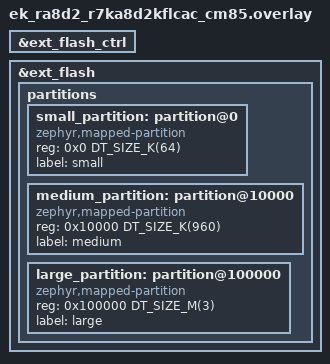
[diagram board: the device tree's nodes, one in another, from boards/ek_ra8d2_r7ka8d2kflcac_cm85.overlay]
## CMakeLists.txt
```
# SPDX-License-Identifier: Apache-2.0

cmake_minimum_required(VERSION 3.28.0)
find_package(Zephyr REQUIRED HINTS $ENV{ZEPHYR_BASE})
project(littlefs)

FILE(GLOB app_sources src/*.c)
# LittleFS opens files for RW by default if no flags given and crashes,
# instead of returning error when attempting to perform operation that
# a file has not been opened for.
target_compile_definitions(app PRIVATE
  BYPASS_FS_OPEN_FLAGS_LFS_ASSERT_CRASH
  BYPASS_FS_OPEN_FLAGS_LFS_RW_IS_DEFAULT
)
target_sources(app PRIVATE
  ${app_sources}
  ../common/test_fs_util.c
  ../common/test_fs_open_flags.c
  ../common/test_fs_dirops.c
  ../common/test_fs_basic.c
  ../common/test_fs_mount_flags.c
  ../common/test_fs_mkfs.c
  ../common/test_fs_gc.c
)
```

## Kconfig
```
# SPDX-License-Identifier: Apache-2.0
# Copyright (c) 2020 Nordic Semiconductor ASA

mainmenu "littlefs core functionality test"

source "Kconfig.zephyr"

config APP_TEST_CUSTOM
	bool "Select to test additional custom filesystem configurations"
```

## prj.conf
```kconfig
CONFIG_FILE_SYSTEM=y
CONFIG_FILE_SYSTEM_MKFS=y
CONFIG_FILE_SYSTEM_GC=y
CONFIG_FILE_SYSTEM_LITTLEFS=y
CONFIG_MAIN_STACK_SIZE=4096

# Performance tests need custom buffer allocation
CONFIG_COMMON_LIBC_MALLOC_ARENA_SIZE=8192

# FS abstraction layer is noisy so it's off.  Turn it on to see the
# littlefs configuration parameters.
#CONFIG_LOG=y
#CONFIG_FS_LOG_LEVEL_DBG=y

CONFIG_FLASH=y
CONFIG_FLASH_MAP=y

CONFIG_ZTEST=y
CONFIG_ZTEST_STACK_SIZE=4096
```

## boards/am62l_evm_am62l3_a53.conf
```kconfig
#
# SPDX-FileCopyrightText: 2026 Texas Instruments Incorporated
#
# SPDX-License-Identifier: Apache-2.0
#

CONFIG_FS_LITTLEFS_PROG_SIZE=256
CONFIG_FS_LITTLEFS_CACHE_SIZE=256
```

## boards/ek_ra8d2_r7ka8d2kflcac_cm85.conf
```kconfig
# Copyright (c) 2026 Renesas Electronics Corporation
# SPDX-License-Identifier: Apache-2.0

CONFIG_FS_LITTLEFS_PROG_SIZE=128
CONFIG_FS_LITTLEFS_CACHE_SIZE=128
CONFIG_HEAP_MEM_POOL_SIZE=2048
```

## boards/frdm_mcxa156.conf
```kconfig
# Copyright 2025 NXP
# SPDX-License-Identifier: Apache-2.0

CONFIG_FS_LITTLEFS_PROG_SIZE=128
CONFIG_FS_LITTLEFS_CACHE_SIZE=256
```

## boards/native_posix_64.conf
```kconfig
CONFIG_FLASH_NATIVE_POSIX_SECTOR_SIZE=4
```

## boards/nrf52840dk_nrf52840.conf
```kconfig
#
# Copyright (c) 2019 Peter Bigot Consulting, LLC
# Copyright (c) 2019 Nordic Semiconductor ASA
#
# SPDX-License-Identifier: Apache-2.0
#

CONFIG_NORDIC_QSPI_NOR_FLASH_LAYOUT_PAGE_SIZE=4096
```

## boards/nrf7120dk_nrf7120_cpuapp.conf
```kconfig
#
# Copyright (c) 2026 Nordic Semiconductor ASA
#
# SPDX-License-Identifier: Apache-2.0
#

CONFIG_FLASH_MSPI_NOR_LAYOUT_PAGE_SIZE=4096
```

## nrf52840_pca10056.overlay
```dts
/*
 * Copyright (c) 2019 Peter Bigot Consulting, LLC
 *
 * SPDX-License-Identifier: Apache-2.0
 */

&mx25r64 {
	partitions {
		compatible = "fixed-partitions";
		#address-cells = <1>;
		#size-cells = <1>;

 		partition@0 {
			label = "small";
			reg = <0x00000000 0x00010000>;
		};
		partition@200000 {
			label = "medium";
			reg = <0x00010000 0x000F0000>;
		};
		partition@220000 {
			label = "large";
			reg = <0x00100000 0x00300000>;
		};
	};
};
```

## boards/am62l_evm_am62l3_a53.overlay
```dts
/*
 * SPDX-FileCopyrightText: 2026 Texas Instruments Incorporated
 *
 * SPDX-License-Identifier: Apache-2.0
 */

&flash0_memory {
	partitions {
		compatible = "fixed-partitions";
		#address-cells = <1>;
		#size-cells = <1>;

		small_partition: partition@0 {
			label = "small";
			reg = <0x00000000 DT_SIZE_M(4)>;
		};

		medium_partition: partition@400000 {
			label = "medium";
			reg = <0x00400000 DT_SIZE_M(6)>;
		};

		large_partition: partition@800000 {
			label = "large";
			reg = <0x00800000 DT_SIZE_M(8)>;
		};
	};
};
```

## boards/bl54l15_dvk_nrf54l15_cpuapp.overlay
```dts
/*
 * Copyright (c) 2024 Nordic Semiconductor ASA
 * Copyright (c) 2025 Ezurio LLC
 *
 * SPDX-License-Identifier: Apache-2.0
 */

/delete-node/ &slot0_ns_partition;
/delete-node/ &slot1_partition;
/delete-node/ &slot1_ns_partition;

&cpuapp_rram {
	partitions {
		compatible = "fixed-partitions";
		#address-cells = <1>;
		#size-cells = <1>;

		small_partition: partition@67000 {
			label = "small";
			reg = <0x00067000 0x00010000>;
		};
	};
};
```

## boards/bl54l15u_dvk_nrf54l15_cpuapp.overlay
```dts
/*
 * Copyright (c) 2024 Nordic Semiconductor ASA
 * Copyright (c) 2025 Ezurio LLC
 *
 * SPDX-License-Identifier: Apache-2.0
 */

/delete-node/ &slot1_partition;

&cpuapp_rram {
	partitions {
		compatible = "fixed-partitions";
		#address-cells = <1>;
		#size-cells = <1>;

		small_partition: partition@b6000 {
			reg = <0x000b6000 0x00010000>;
			label = "small";
		};
	};
};
```

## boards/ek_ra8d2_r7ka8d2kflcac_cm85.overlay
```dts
/*
 * Copyright (c) 2026 Renesas Electronics Corporation
 * SPDX-License-Identifier: Apache-2.0
 */

/delete-node/ &storage_partition;

&ext_flash_ctrl {
	status = "okay";
};

&ext_flash {
	status = "okay";

	partitions {
		ranges;
		#address-cells = <1>;
		#size-cells = <1>;

		small_partition: partition@0 {
			compatible = "zephyr,mapped-partition";
			reg = <0x0 DT_SIZE_K(64)>;
			label = "small";
		};

		medium_partition: partition@10000 {
			compatible = "zephyr,mapped-partition";
			reg = <0x10000 DT_SIZE_K(960)>;
			label = "medium";
		};

		large_partition: partition@100000 {
			compatible = "zephyr,mapped-partition";
			reg = <0x100000 DT_SIZE_M(3)>;
			label = "large";
		};
	};
};
```

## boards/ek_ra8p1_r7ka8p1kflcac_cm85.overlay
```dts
/*
 * Copyright (c) 2026 Renesas Electronics Corporation
 * SPDX-License-Identifier: Apache-2.0
 */

/delete-node/ &storage_partition;

&ext_flash_ctrl {
	status = "okay";
};

&ext_flash {
	status = "okay";

	partitions {
		#address-cells = <1>;
		#size-cells = <1>;
		ranges;

		small_partition: partition@0 {
			compatible = "zephyr,mapped-partition";
			label = "small";
			reg = <0x0 DT_SIZE_K(64)>;
		};

		medium_partition: partition@10000 {
			compatible = "zephyr,mapped-partition";
			label = "medium";
			reg = <0x10000 DT_SIZE_K(960)>;
		};

		large_partition: partition@100000 {
			compatible = "zephyr,mapped-partition";
			label = "large";
			reg = <0x100000 DT_SIZE_M(3)>;
		};
	};
};
```

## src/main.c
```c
/*
 * Copyright (c) 2019 Peter Bigot Consulting, LLC
 *
 * SPDX-License-Identifier: Apache-2.0
 */

#include <string.h>
#include <zephyr/ztest.h>
#include "testfs_tests.h"
#include "testfs_lfs.h"

ZTEST_SUITE(littlefs, NULL, NULL, NULL, NULL, NULL);
```

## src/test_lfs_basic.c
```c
/*
 * Copyright (c) 2019 Peter Bigot Consulting, LLC
 *
 * SPDX-License-Identifier: Apache-2.0
 */

/* Basic littlefs operations:
 * * create
 * * write
 * * stat
 * * read
 * * seek
 * * tell
 * * truncate
 * * unlink
 * * sync
 */

#include <string.h>
#include <zephyr/ztest.h>
#include "testfs_tests.h"
#include "testfs_lfs.h"
#include <lfs.h>

#include <zephyr/fs/littlefs.h>

static int mount(struct fs_mount_t *mp)
{
	TC_PRINT("mounting %s\n", mp->mnt_point);

	zassert_equal(fs_mount(mp), 0,
		      "mount failed");

	return TC_PASS;
}

static int clear_partition(struct fs_mount_t *mp)
{
	TC_PRINT("clearing partition %s\n", mp->mnt_point);

	zassert_equal(testfs_lfs_wipe_partition(mp),
		      TC_PASS,
		      "failed to wipe partition");

	return TC_PASS;
}

static int clean_statvfs(const struct fs_mount_t *mp)
{
	struct fs_statvfs stat;

	TC_PRINT("checking clean statvfs of %s\n", mp->mnt_point);

	zassert_equal(fs_statvfs(mp->mnt_point, &stat), 0,
		      "statvfs failed");

	TC_PRINT("%s: bsize %lu ; frsize %lu ; blocks %lu ; bfree %lu\n",
		 mp->mnt_point,
		 stat.f_bsize, stat.f_frsize, stat.f_blocks, stat.f_bfree);
	zassert_equal(stat.f_bsize, CONFIG_FS_LITTLEFS_PROG_SIZE,
		      "bsize fail");
	zassert_equal(stat.f_bfree, stat.f_blocks - 2U,
		      "bfree fail");

	return TC_PASS;
}

static int check_medium(void)
{
	struct fs_mount_t *mp = &testfs_medium_mnt;
	struct fs_statvfs stat;

	zassert_equal(clear_partition(mp), TC_PASS,
		      "clear partition failed");

	zassert_equal(fs_mount(mp), 0,
		      "medium mount failed");

	zassert_equal(fs_statvfs(mp->mnt_point, &stat), 0,
		      "statvfs failed");

	TC_PRINT("%s: bsize %lu ; frsize %lu ; blocks %lu ; bfree %lu\n",
		 mp->mnt_point,
		 stat.f_bsize, stat.f_frsize, stat.f_blocks, stat.f_bfree);
	zassert_equal(stat.f_bsize, MEDIUM_IO_SIZE,
		      "bsize fail");
	zassert_equal(stat.f_bfree, stat.f_blocks - 2U,
		      "bfree fail");

	zassert_equal(fs_unmount(mp), 0,
		      "medium unmount failed");

	return TC_PASS;
}

static int check_large(void)
{
	struct fs_mount_t *mp = &testfs_large_mnt;
	struct fs_statvfs stat;

	zassert_equal(clear_partition(mp), TC_PASS,
		      "clear partition failed");

	zassert_equal(fs_mount(mp), 0,
		      "large mount failed");

	zassert_equal(fs_statvfs(mp->mnt_point, &stat), 0,
		      "statvfs failed");

	TC_PRINT("%s: bsize %lu ; frsize %lu ; blocks %lu ; bfree %lu\n",
		 mp->mnt_point,
		 stat.f_bsize, stat.f_frsize, stat.f_blocks, stat.f_bfree);
	zassert_equal(stat.f_bsize, LARGE_IO_SIZE,
		      "bsize fail");
	zassert_equal(stat.f_bfree, stat.f_blocks - 2U,
		      "bfree fail");

	zassert_equal(fs_unmount(mp), 0,
		      "large unmount failed");

	return TC_PASS;
}

static int num_files(struct fs_mount_t *mp)
{
	struct testfs_path path;
	char name[2] = { 0 };
	const char *pstr;
	struct fs_file_t files[CONFIG_FS_LITTLEFS_NUM_FILES];
	size_t fi = 0;
	int rc;

	memset(files, 0, sizeof(files));

	TC_PRINT("CONFIG_FS_LITTLEFS_NUM_FILES=%u\n", CONFIG_FS_LITTLEFS_NUM_FILES);
	while (fi < ARRAY_SIZE(files)) {
		struct fs_file_t *const file = &files[fi];

		name[0] = 'A' + fi;
		pstr = testfs_path_init(&path, mp,
					name,
					TESTFS_PATH_END);

		TC_PRINT("opening %s\n", pstr);
		rc = fs_open(file, pstr, FS_O_CREATE | FS_O_RDWR);
		zassert_equal(rc, 0, "open %s failed: %d", pstr, rc);

		rc = testfs_write_incrementing(file, 0, TESTFS_BUFFER_SIZE);
		zassert_equal(rc, TESTFS_BUFFER_SIZE, "write %s failed: %d", pstr, rc);

		++fi;
	}

	while (fi-- != 0)  {
		struct fs_file_t *const file = &files[fi];

		name[0] = 'A' + fi;
		pstr = testfs_path_init(&path, mp,
					name,
					TESTFS_PATH_END);

		TC_PRINT("Close and unlink %s\n", pstr);

		rc = fs_close(file);
		zassert_equal(rc, 0, "close %s failed: %d", pstr, rc);

		rc = fs_unlink(pstr);
		zassert_equal(rc, 0, "unlink %s failed: %d", pstr, rc);
	}

	return TC_PASS;
}

static int num_dirs(struct fs_mount_t *mp)
{
	struct testfs_path path;
	char name[3] = "Dx";
	const char *pstr;
	struct fs_dir_t dirs[CONFIG_FS_LITTLEFS_NUM_DIRS];
	size_t di = 0;
	int rc;

	memset(dirs, 0, sizeof(dirs));

	TC_PRINT("CONFIG_FS_LITTLEFS_NUM_DIRS=%u\n", CONFIG_FS_LITTLEFS_NUM_DIRS);
	while (di < ARRAY_SIZE(dirs)) {
		struct fs_dir_t *const dir = &dirs[di];

		name[1] = 'A' + di;
		pstr = testfs_path_init(&path, mp,
					name,
					TESTFS_PATH_END);

		TC_PRINT("making and opening directory %s\n", pstr);
		rc = fs_mkdir(pstr);
		zassert_equal(rc, 0, "mkdir %s failed: %d", pstr, rc);

		rc = fs_opendir(dir, pstr);
		zassert_equal(rc, 0, "opendir %s failed: %d", name, rc);

		++di;
	}

	while (di-- != 0)  {
		struct fs_dir_t *const dir = &dirs[di];

		name[1] = 'A' + di;
		pstr = testfs_path_init(&path, mp,
					name,
					TESTFS_PATH_END);

		TC_PRINT("Close and rmdir %s\n", pstr);

		rc = fs_closedir(dir);
		zassert_equal(rc, 0, "closedir %s failed: %d", name, rc);

		rc = fs_unlink(pstr);
		zassert_equal(rc, 0, "unlink %s failed: %d", name, rc);
	}

	return TC_PASS;
}

static int dir_rewind_and_utime(struct fs_mount_t *mp)
{
	struct testfs_path path;
	struct fs_dir_t dir;
	struct fs_dirent entry;
	int rc;

	fs_dir_t_init(&dir);

	rc = fs_opendir(&dir, testfs_path_init(&path, mp, TESTFS_PATH_END));
	zassert_equal(rc, 0, "opendir failed: %d", rc);

	do {
		rc = fs_readdir(&dir, &entry);
		zassert_equal(rc, 0, "readdir failed: %d", rc);
	} while (entry.name[0] != '\0');

	rc = fs_rewinddir(&dir);
	zassert_equal(rc, 0, "rewinddir failed: %d", rc);

	rc = fs_readdir(&dir, &entry);
	zassert_equal(rc, 0, "readdir after rewind failed: %d", rc);
	zassert_not_equal(entry.name[0], '\0', "rewound dir is empty");

	rc = fs_closedir(&dir);
	zassert_equal(rc, 0, "closedir failed: %d", rc);

	/* littlefs records no timestamps */
	rc = fs_utime(testfs_path_init(&path, mp, "any", TESTFS_PATH_END), NULL);
	zassert_equal(rc, -ENOTSUP, "expected -ENOTSUP got %d", rc);

	return TC_PASS;
}

void test_fs_basic(void);

/* Mount structure needed by test_fs_basic tests. */
struct fs_mount_t *fs_basic_test_mp = &testfs_small_mnt;

ZTEST(littlefs, test_lfs_basic)
{
	struct fs_mount_t *mp = &testfs_small_mnt;

	zassert_equal(clear_partition(mp), TC_PASS,
		      "clear partition failed");

	/* Common basic tests.
	 * (File system is mounted and unmounted during that test.)
	 */
	test_fs_basic();

	/* LittleFS specific tests */

	zassert_equal(mount(mp), TC_PASS,
		      "clean mount failed");

	zassert_equal(clean_statvfs(mp), TC_PASS,
		      "clean statvfs failed");

	zassert_equal(num_files(mp), TC_PASS,
		      "num_files failed");

	zassert_equal(num_dirs(mp), TC_PASS,
		      "num_dirs failed");

	zassert_equal(dir_rewind_and_utime(mp), TC_PASS,
		      "dir_rewind_and_utime failed");

	TC_PRINT("unmounting %s\n", mp->mnt_point);
	zassert_equal(fs_unmount(mp), 0,
		      "unmount small failed");

	if (IS_ENABLED(CONFIG_APP_TEST_CUSTOM)) {
		zassert_equal(check_medium(), TC_PASS,
			      "check medium failed");

		zassert_equal(check_large(), TC_PASS,
			      "check large failed");
	}
}
```

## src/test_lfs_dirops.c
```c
/*
 * Copyright (c) 2019 Peter Bigot Consulting, LLC
 *
 * SPDX-License-Identifier: Apache-2.0
 */

/* Directory littlefs operations:
 * * mkdir
 * * opendir
 * * readdir
 * * closedir
 * * rename
 */

#include <string.h>
#include <zephyr/ztest.h>
#include "testfs_tests.h"
#include "testfs_lfs.h"
#include <lfs.h>

#include <zephyr/fs/littlefs.h>

void test_fs_dirops(void);

/* Mount structure needed by test_fs_basic tests. */
struct fs_mount_t *fs_dirops_test_mp = &testfs_small_mnt;

ZTEST(littlefs, test_lfs_dirops)
{
	struct fs_mount_t *mp = &testfs_small_mnt;

	zassert_equal(testfs_lfs_wipe_partition(mp),
		      TC_PASS,
		      "failed to wipe partition");

	/* Common dirops tests.
	 * (File system is mounted and unmounted during that test.)
	 */
	test_fs_dirops();
}

FS_LITTLEFS_DECLARE_DEFAULT_CONFIG(root_lfs);
static struct fs_mount_t root_mnt = {
	.type = FS_LITTLEFS,
	.fs_data = &root_lfs,
	.mnt_point = "/",
};

ZTEST(littlefs, test_lfs_opendir_root_mount)
{
	struct fs_file_t file;
	struct fs_dir_t dir;
	struct fs_dirent entry;
	bool found = false;
	int rc;

	root_mnt.storage_dev = testfs_small_mnt.storage_dev;
	zassert_equal(testfs_lfs_wipe_partition(&root_mnt), TC_PASS, "failed to wipe partition");
	zassert_equal(fs_mount(&root_mnt), 0, "failed to mount at /");

	fs_file_t_init(&file);
	zassert_equal(fs_open(&file, "/root_file", FS_O_CREATE | FS_O_WRITE), 0,
		      "failed to create /root_file");
	zassert_equal(fs_close(&file), 0, "failed to close /root_file");

	fs_dir_t_init(&dir);
	zassert_equal(fs_opendir(&dir, "/"), 0, "failed to open /");
	do {
		rc = fs_readdir(&dir, &entry);
		if ((rc == 0) && (strcmp(entry.name, "root_file") == 0)) {
			found = true;
		}
	} while ((rc == 0) && (entry.name[0] != '\0'));
	zassert_equal(fs_closedir(&dir), 0, "failed to close /");
	zassert_equal(fs_unmount(&root_mnt), 0, "failed to unmount /");

	zassert_equal(rc, 0, "readdir of / failed: %d", rc);
	zassert_true(found, "root_file not listed by readdir of /");
}
```

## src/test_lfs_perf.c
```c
/*
 * Copyright (c) 2019 Peter Bigot Consulting, LLC
 *
 * SPDX-License-Identifier: Apache-2.0
 */

/* littlefs performance testing */

#include <string.h>
#include <stdlib.h>
#include <zephyr/kernel.h>
#include <zephyr/ztest.h>
#include "testfs_tests.h"
#include "testfs_lfs.h"
#include <lfs.h>

#include <zephyr/fs/littlefs.h>

#define HELLO "hello"
#define GOODBYE "goodbye"

static int write_read(const char *tag,
		      struct fs_mount_t *mp,
		      size_t buf_size,
		      size_t nbuf)
{
	const struct lfs_config *lcp = &((const struct fs_littlefs *)mp->fs_data)->cfg;
	struct testfs_path path;
	struct fs_statvfs vfs;
	struct fs_dirent stat;
	struct fs_file_t file;
	size_t total = nbuf * buf_size;
	uint32_t t0;
	uint32_t t1;
	uint8_t *buf;
	int rc;
	int rv = TC_FAIL;

	fs_file_t_init(&file);
	TC_PRINT("clearing %s for %s write/read test\n",
		 mp->mnt_point, tag);
	if (testfs_lfs_wipe_partition(mp) != TC_PASS) {
		return TC_FAIL;
	}

	rc = fs_mount(mp);
	if (rc != 0) {
		TC_PRINT("Mount %s failed: %d\n", mp->mnt_point, rc);
		return TC_FAIL;
	}

	rc = fs_statvfs(mp->mnt_point, &vfs);
	if (rc != 0) {
		TC_PRINT("statvfs %s failed: %d\n", mp->mnt_point, rc);
		goto out_mnt;
	}

	TC_PRINT("%s: bsize %lu ; frsize %lu ; blocks %lu ; bfree %lu\n",
		 mp->mnt_point,
		 vfs.f_bsize, vfs.f_frsize, vfs.f_blocks, vfs.f_bfree);
	TC_PRINT("read_size %u ; prog_size %u ; cache_size %u ; lookahead_size %u\n",
		 lcp->read_size, lcp->prog_size, lcp->cache_size, lcp->lookahead_size);

	testfs_path_init(&path, mp,
			 "data",
			 TESTFS_PATH_END);

	buf = calloc(buf_size, sizeof(uint8_t));
	if (buf == NULL) {
		TC_PRINT("Failed to allocate %zu-byte buffer\n", buf_size);
		goto out_mnt;
	}

	for (size_t i = 0; i < buf_size; ++i) {
		buf[i] = i;
	}

	TC_PRINT("creating and writing %zu %zu-byte blocks\n",
		 nbuf, buf_size);

	rc = fs_open(&file, path.path, FS_O_CREATE | FS_O_RDWR);
	if (rc != 0) {
		TC_PRINT("Failed to open %s for write: %d\n", path.path, rc);
		goto out_buf;
	}

	t0 = k_uptime_get_32();
	for (size_t i = 0; i < nbuf; ++i) {
		rc = fs_write(&file, buf, buf_size);
		if (buf_size != rc) {
			TC_PRINT("Failed to write buf %zu: %d\n", i, rc);
			goto out_file;
		}
	}
	t1 = k_uptime_get_32();

	if (t1 == t0) {
		t1++;
	}

	(void)fs_close(&file);

	rc = fs_stat(path.path, &stat);
	if (rc != 0) {
		TC_PRINT("Failed to stat %s: %d\n", path.path, rc);
		goto out_buf;
	}

	if (stat.size != total) {
		TC_PRINT("File size %zu not %zu\n", stat.size, total);
		goto out_buf;
	}

	TC_PRINT("%s write %zu * %zu = %zu bytes in %u ms: "
		 "%u By/s, %u KiBy/s\n",
		 tag, nbuf, buf_size, total, (t1 - t0),
		 (uint32_t)(total * 1000U / (t1 - t0)),
		 (uint32_t)(total * 1000U / (t1 - t0) / 1024U));

	rc = fs_open(&file, path.path, FS_O_CREATE | FS_O_RDWR);
	if (rc != 0) {
		TC_PRINT("Failed to open %s for write: %d\n", path.path, rc);
		goto out_buf;
	}

	t0 = k_uptime_get_32();
	for (size_t i = 0; i < nbuf; ++i) {
		rc = fs_read(&file, buf, buf_size);
		if (buf_size != rc) {
			TC_PRINT("Failed to read buf %zu: %d\n", i, rc);
			goto out_file;
		}
	}
	t1 = k_uptime_get_32();

	if (t1 == t0) {
		t1++;
	}

	TC_PRINT("%s read %zu * %zu = %zu bytes in %u ms: "
		 "%u By/s, %u KiBy/s\n",
		 tag, nbuf, buf_size, total, (t1 - t0),
		 (uint32_t)(total * 1000U / (t1 - t0)),
		 (uint32_t)(total * 1000U / (t1 - t0) / 1024U));

	rv = TC_PASS;

out_file:
	(void)fs_close(&file);

out_buf:
	free(buf);

out_mnt:
	(void)fs_unmount(mp);

	return rv;
}

static int custom_write_test(const char *tag,
			     const struct fs_mount_t *mp,
			     const struct lfs_config *cfgp,
			     size_t buf_size,
			     size_t nbuf)
{
	struct fs_littlefs data = {
		.cfg = *cfgp,
	};
	struct fs_mount_t lfs_mnt = {
		.type = FS_LITTLEFS,
		.fs_data = &data,
		.storage_dev = mp->storage_dev,
		.mnt_point = mp->mnt_point,
	};
	struct lfs_config *lcp = &data.cfg;
	int rv = TC_FAIL;

	if (lcp->cache_size == 0) {
		lcp->cache_size = CONFIG_FS_LITTLEFS_CACHE_SIZE;
	}
	if (lcp->lookahead_size == 0) {
		lcp->lookahead_size = CONFIG_FS_LITTLEFS_LOOKAHEAD_SIZE;
	}

	lcp->read_buffer = malloc(lcp->cache_size);
	lcp->prog_buffer = malloc(lcp->cache_size);
	lcp->lookahead_buffer = malloc(lcp->lookahead_size);

	TC_PRINT("bufs %p %p %p\n", lcp->read_buffer, lcp->prog_buffer, lcp->lookahead_buffer);

	if ((lcp->read_buffer == NULL)
	    || (lcp->prog_buffer == NULL)
	    || (lcp->lookahead_buffer == NULL)) {
		TC_PRINT("%s buffer allocation failed\n", tag);
		goto out_free;
	}

	rv = write_read(tag, &lfs_mnt, buf_size, nbuf);

out_free:
	if (lcp->read_buffer) {
		free(lcp->read_buffer);
	}
	if (lcp->prog_buffer) {
		free(lcp->prog_buffer);
	}
	if (lcp->lookahead_buffer) {
		free(lcp->lookahead_buffer);
	}

	return rv;
}

static int small_8_1K_cust(void)
{
	struct lfs_config cfg = {
		.read_size = LARGE_IO_SIZE,
		.prog_size = LARGE_IO_SIZE,
		.cache_size = LARGE_CACHE_SIZE,
		.lookahead_size = LARGE_LOOKAHEAD_SIZE
	};

	return custom_write_test("small 8x1K bigfile", &testfs_small_mnt, &cfg, 1024, 8);
}

ZTEST(littlefs, test_lfs_perf)
{
	k_sleep(K_MSEC(100));   /* flush log messages */
	zassert_equal(write_read("small 8x1K dflt",
				 &testfs_small_mnt,
				 1024, 8),
		      TC_PASS,
		      "failed");

	if (IS_ENABLED(CONFIG_APP_TEST_CUSTOM)) {
		k_sleep(K_MSEC(100));   /* flush log messages */
		zassert_equal(small_8_1K_cust(), TC_PASS,
			      "failed");

		k_sleep(K_MSEC(100));   /* flush log messages */
		zassert_equal(write_read("medium 32x2K dflt",
					 &testfs_medium_mnt,
					 2048, 32),
			      TC_PASS,
			      "failed");

		k_sleep(K_MSEC(100));   /* flush log messages */
		zassert_equal(write_read("large 64x4K dflt",
					 &testfs_large_mnt,
					 4096, 64),
			      TC_PASS,
			      "failed");
	}
}
```

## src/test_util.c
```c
/*
 * Copyright (c) 2019 Peter Bigot Consulting, LLC
 *
 * SPDX-License-Identifier: Apache-2.0
 */

/* Tests of functions in testfs_util */

#include <string.h>
#include <zephyr/ztest.h>
#include "testfs_tests.h"
#include "../../common/test_fs_util.h"

#define MNT "/mnt"
#define ELT1 "a"
#define ELT2 "b"

static struct testfs_path path;
static const struct fs_mount_t mnt = {
	.mnt_point = MNT,
};

static inline struct testfs_path *reset_path()
{
	testfs_path_init(&path, &mnt, TESTFS_PATH_END);
	return &path;
}

ZTEST(littlefs, test_util_path_init_base)
{
	zassert_equal(testfs_path_init(&path, NULL, TESTFS_PATH_END),
		      path.path,
		      "bad root init return");
	zassert_str_equal(path.path, "/", "bad root init path");

	zassert_equal(testfs_path_init(&path, &mnt, TESTFS_PATH_END),
		      path.path,
		      "bad mnt init return");
	zassert_str_equal(path.path, mnt.mnt_point, "bad mnt init path");

	if (IS_ENABLED(CONFIG_DEBUG)) {
		struct fs_mount_t invalid = {
			.mnt_point = "relative",
		};

		/* Apparently no way to verify this without panic. */
		testfs_path_init(&path, &invalid, TESTFS_PATH_END);
	}
}

ZTEST(littlefs, test_util_path_init_overrun)
{
	char overrun[TESTFS_PATH_MAX + 2] = "/";
	size_t overrun_max = sizeof(overrun) - 1;
	size_t path_max = sizeof(path.path) - 1;
	struct fs_mount_t overrun_mnt = {
		.mnt_point = overrun,
	};

	zassert_true(path_max < overrun_max,
		     "path length requirements unmet");

	memset(overrun + 1, 'A', overrun_max - 1);

	zassert_equal(testfs_path_init(&path, &overrun_mnt, TESTFS_PATH_END),
		      path.path,
		      "bad overrun init return");
	zassert_true(strcmp(path.path, overrun) < 0,
		     "bad overrun init");
	zassert_equal(strncmp(path.path, overrun, path_max),
		      0,
		      "bad overrun path");
	zassert_equal(path.path[path_max], '\0',
		      "missing overrun EOS");
}

ZTEST(littlefs, test_util_path_init_extended)
{
	zassert_str_equal(testfs_path_init(&path, &mnt, ELT1, TESTFS_PATH_END),
			  MNT "/" ELT1, "bad mnt init elt1");

	zassert_str_equal(testfs_path_init(&path, &mnt, ELT1, ELT2, TESTFS_PATH_END),
			  MNT "/" ELT1 "/" ELT2, "bad mnt init elt1 elt2");
}

ZTEST(littlefs, test_util_path_extend)
{
	zassert_str_equal(testfs_path_extend(reset_path(), TESTFS_PATH_END),
			  MNT, "empty extend failed");

	zassert_str_equal(testfs_path_extend(reset_path(), ELT2, TESTFS_PATH_END),
			  MNT "/" ELT2, "elt extend failed");

	zassert_str_equal(testfs_path_extend(reset_path(), ELT1, ELT2, TESTFS_PATH_END),
			  MNT "/" ELT1 "/" ELT2, "elt1 elt2 extend failed");
}

ZTEST(littlefs, test_util_path_extend_up)
{
	zassert_str_equal(testfs_path_extend(reset_path(), ELT2, "..", ELT1, TESTFS_PATH_END),
			  MNT "/" ELT1, "elt elt2, up, elt1 failed");

	zassert_str_equal(testfs_path_extend(reset_path(), "..", TESTFS_PATH_END),
			  "/", "up strip mnt failed");

	zassert_str_equal(testfs_path_extend(reset_path(), "..", "..", TESTFS_PATH_END),
			  "/", "up from root failed");
}

ZTEST(littlefs, test_util_path_extend_overrun)
{
	char long_elt[TESTFS_PATH_MAX];

	memset(long_elt, 'a', sizeof(long_elt) - 1);
	long_elt[sizeof(long_elt) - 1] = '\0';

	zassert_str_equal(testfs_path_extend(reset_path(), long_elt, ELT1, TESTFS_PATH_END),
			  MNT, "stop at overrun failed");
}
```

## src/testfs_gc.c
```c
/*
 * Copyright (c) 2025 Trackunit
 *
 * SPDX-License-Identifier: Apache-2.0
 */

#include <zephyr/ztest.h>
#include <zephyr/fs/littlefs.h>
#include "testfs_tests.h"
#include "testfs_lfs.h"

void test_fs_gc_simple(void);

struct fs_mount_t *fs_gc_mp = &testfs_small_mnt;

static void cleanup(struct fs_mount_t *mp)
{
	TC_PRINT("Clean %s\n", mp->mnt_point);

	zassert_equal(testfs_lfs_wipe_partition(mp), TC_PASS,
		      "Failed to clean partition");
}

ZTEST(littlefs, test_fs_gc_simple_lfs)
{
	cleanup(fs_gc_mp);

	test_fs_gc_simple();
}
```

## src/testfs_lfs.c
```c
/*
 * Copyright (c) 2019 Peter Bigot Consulting, LLC
 *
 * SPDX-License-Identifier: Apache-2.0
 */

#include <zephyr/ztest.h>
#include <zephyr/fs/littlefs.h>
#include <zephyr/storage/flash_map.h>
#include "testfs_lfs.h"

#define SMALL_PARTITION		small_partition
#define SMALL_PARTITION_ID	PARTITION_ID(SMALL_PARTITION)

#define MEDIUM_PARTITION	medium_partition
#define MEDIUM_PARTITION_ID	PARTITION_ID(MEDIUM_PARTITION)

#define LARGE_PARTITION		large_partition
#define LARGE_PARTITION_ID	PARTITION_ID(LARGE_PARTITION)

FS_LITTLEFS_DECLARE_DEFAULT_CONFIG(small);
struct fs_mount_t testfs_small_mnt = {
	.type = FS_LITTLEFS,
	.fs_data = &small,
	.storage_dev = (void *)SMALL_PARTITION_ID,
	.mnt_point = TESTFS_MNT_POINT_SMALL,
};

#if CONFIG_APP_TEST_CUSTOM
FS_LITTLEFS_DECLARE_CUSTOM_CONFIG(medium, 4, MEDIUM_IO_SIZE, MEDIUM_IO_SIZE,
				  MEDIUM_CACHE_SIZE, MEDIUM_LOOKAHEAD_SIZE);
struct fs_mount_t testfs_medium_mnt = {
	.type = FS_LITTLEFS,
	.fs_data = &medium,
	.storage_dev = (void *)MEDIUM_PARTITION_ID,
	.mnt_point = TESTFS_MNT_POINT_MEDIUM,
};

static uint8_t large_read_buffer[LARGE_CACHE_SIZE];
static uint8_t large_prog_buffer[LARGE_CACHE_SIZE];
static uint32_t large_lookahead_buffer[LARGE_LOOKAHEAD_SIZE / 4U];
static struct fs_littlefs large = {
	.cfg = {
		.read_size = LARGE_IO_SIZE,
		.prog_size = LARGE_IO_SIZE,
		.cache_size = LARGE_CACHE_SIZE,
		.lookahead_size = LARGE_LOOKAHEAD_SIZE,
		.read_buffer = large_read_buffer,
		.prog_buffer = large_prog_buffer,
		.lookahead_buffer = large_lookahead_buffer,
	},
};
struct fs_mount_t testfs_large_mnt = {
	.type = FS_LITTLEFS,
	.fs_data = &large,
	.storage_dev = (void *)LARGE_PARTITION_ID,
	.mnt_point = TESTFS_MNT_POINT_LARGE,
};

#endif /* CONFIG_APP_TEST_CUSTOM */

int testfs_lfs_wipe_partition(const struct fs_mount_t *mp)
{
	unsigned int id = (uintptr_t)mp->storage_dev;
	const struct flash_area *pfa;
	int rc = flash_area_open(id, &pfa);

	if (rc < 0) {
		TC_PRINT("Error accessing flash area %u [%d]\n",
			 id, rc);
		return TC_FAIL;
	}

	TC_PRINT("Erasing %zu (0x%zx) bytes\n", pfa->fa_size, pfa->fa_size);
	rc = flash_area_flatten(pfa, 0, pfa->fa_size);
	(void)flash_area_close(pfa);

	if (rc < 0) {
		TC_PRINT("Error wiping flash area %u [%d]\n",
			 id, rc);
		return TC_FAIL;
	}

	TC_PRINT("Wiped flash area %u for %s\n", id, mp->mnt_point);
	return TC_PASS;
}
```

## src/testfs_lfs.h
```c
/*
 * Copyright (c) 2019 Peter Bigot Consulting, LLC
 *
 * SPDX-License-Identifier: Apache-2.0
 */

#ifndef _ZEPHYR_TESTS_SUBSYS_FS_LITTLEFS_TESTFS_LFS_H_
#define _ZEPHYR_TESTS_SUBSYS_FS_LITTLEFS_TESTFS_LFS_H_

#include <zephyr/fs/fs.h>
#include "../../common/test_fs_util.h"

#define TESTFS_MNT_POINT_SMALL "/sml"
#define TESTFS_MNT_POINT_MEDIUM "/med"
#define TESTFS_MNT_POINT_LARGE "/lrg"

extern struct fs_mount_t testfs_small_mnt;
extern struct fs_mount_t testfs_medium_mnt;
extern struct fs_mount_t testfs_large_mnt;

#define MEDIUM_IO_SIZE 64
#define MEDIUM_CACHE_SIZE 256
#define MEDIUM_LOOKAHEAD_SIZE 64

#define LARGE_IO_SIZE 256
#define LARGE_CACHE_SIZE 1024
#define LARGE_LOOKAHEAD_SIZE 128

/** Wipe all data from the flash partition associated with the given
 * mount point.
 *
 * This will cause it to be reformatted the next time it is mounted.
 *
 * @param mp pointer to the mount point data.  The flash partition ID
 * must be encoded in the fs_mount_t::storage_dev pointer.
 *
 * @return a standard test result code.
 */
int testfs_lfs_wipe_partition(const struct fs_mount_t *mp);

#endif /* _ZEPHYR_TESTS_SUBSYS_FS_LITTLEFS_TESTFS_LFS_H_ */
```

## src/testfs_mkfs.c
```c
/*
 * Copyright (c) 2022 Antmicro
 *
 * SPDX-License-Identifier: Apache-2.0
 */

#include <zephyr/ztest.h>
#include <zephyr/fs/littlefs.h>
#include "testfs_tests.h"
#include "testfs_lfs.h"

void test_fs_mkfs_ops(void);
void test_fs_mkfs_simple(void);
/* Using smallest partition for this tests as they do not write
 * a lot of data, basically they just check flags.
 */
struct fs_mount_t *fs_mkfs_mp = &testfs_small_mnt;
const int fs_mkfs_type = FS_LITTLEFS;
uintptr_t fs_mkfs_dev_id;
int fs_mkfs_flags;
const char *some_file_path = "/sml/some";
const char *other_dir_path = "/sml/other";

static void cleanup(struct fs_mount_t *mp)
{
	TC_PRINT("Clean %s\n", mp->mnt_point);

	zassert_equal(testfs_lfs_wipe_partition(mp), TC_PASS,
		      "Failed to clean partition");
}

ZTEST(littlefs, test_fs_mkfs_simple_lfs)
{
	cleanup(fs_mkfs_mp);

	fs_mkfs_dev_id = (uintptr_t) testfs_small_mnt.storage_dev;
	test_fs_mkfs_simple();
}

ZTEST(littlefs, test_fs_mkfs_ops_lfs)
{
	cleanup(fs_mkfs_mp);

	fs_mkfs_dev_id = (uintptr_t) testfs_small_mnt.storage_dev;
	test_fs_mkfs_ops();
}

/* Custom config with doubled the prog size */
FS_LITTLEFS_DECLARE_CUSTOM_CONFIG(custom_cfg,
		4,
		CONFIG_FS_LITTLEFS_READ_SIZE,
		CONFIG_FS_LITTLEFS_PROG_SIZE,
		CONFIG_FS_LITTLEFS_CACHE_SIZE,
		CONFIG_FS_LITTLEFS_LOOKAHEAD_SIZE);

ZTEST(littlefs, test_fs_mkfs_custom)
{
	int ret = 0;
	struct fs_statvfs sbuf;
	struct fs_mount_t mnt = testfs_small_mnt;

	cleanup(fs_mkfs_mp);

	ret = fs_mkfs(FS_LITTLEFS, (uintptr_t)testfs_small_mnt.storage_dev, &custom_cfg, 0);
	zassert_equal(ret, 0, "Expected success (ret=%d)", ret);

	mnt.flags = FS_MOUNT_FLAG_NO_FORMAT;
	mnt.fs_data = &custom_cfg;
	ret = fs_mount(&mnt);
	zassert_equal(ret, 0, "Expected success (ret=%d)", ret);

	ret = fs_statvfs(mnt.mnt_point, &sbuf);
	zassert_equal(ret, 0, "Expected success (ret=%d)", ret);

	TC_PRINT("f_bsize= %lu", sbuf.f_bsize);
	/* Prog size is returned in f_bsize field. */
	zassert_equal(sbuf.f_bsize, CONFIG_FS_LITTLEFS_PROG_SIZE);

	ret = fs_unmount(&mnt);
	zassert_equal(ret, 0, "Expected success (ret=%d)", ret);
}
```

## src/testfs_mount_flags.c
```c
/*
 * Copyright (c) 2020 Nordic Semiconductor ASA
 * Copyright (c) 2022 Antmicro
 *
 * SPDX-License-Identifier: Apache-2.0
 */

#include <zephyr/ztest.h>
#include <zephyr/fs/littlefs.h>
#include "testfs_tests.h"
#include "testfs_lfs.h"

void test_fs_mount_flags(void);
/* Using smallest partition for this tests as they do not write
 * a lot of data, basically they just check flags.
 */
struct fs_mount_t *mount_flags_mp = &testfs_small_mnt;

static void cleanup(struct fs_mount_t *mp)
{
	TC_PRINT("Clean %s\n", mp->mnt_point);

	zassert_equal(testfs_lfs_wipe_partition(mp), TC_PASS,
		      "Failed to clean partition");
}

ZTEST(littlefs, test_fs_mount_flags_lfs)
{
	cleanup(mount_flags_mp);

	test_fs_mount_flags();
}

/**
 * @brief littlefs must reject a mount with no pre-allocated fs_data
 */
ZTEST(littlefs, test_fs_mount_null_fs_data)
{
	struct fs_mount_t mp = {
		.type = FS_LITTLEFS,
		.mnt_point = "/nullfs",
		.fs_data = NULL,
	};
	int ret;

	ret = fs_mount(&mp);
	zassert_equal(ret, -EINVAL,
		      "NULL fs_data must be rejected with -EINVAL, got %d", ret);
}
```

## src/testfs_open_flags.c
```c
/*
 * Copyright (c) 2020 Nordic Semiconductor ASA
 *
 * SPDX-License-Identifier: Apache-2.0
 */

#include <zephyr/ztest.h>
#include <zephyr/fs/littlefs.h>
#include "testfs_tests.h"
#include "testfs_lfs.h"

void test_fs_open_flags(void);
/* Expected by test_fs_open_flags() */
const char *test_fs_open_flags_file_path = TESTFS_MNT_POINT_SMALL"/the_file";

static void mount(struct fs_mount_t *mp)
{
	TC_PRINT("Mount %s\n", mp->mnt_point);

	zassert_equal(fs_mount(mp), 0, "Failed to mount partition");
}

static void unmount(struct fs_mount_t *mp)
{
	TC_PRINT("Unmounting %s\n", mp->mnt_point);

	zassert_equal(fs_unmount(mp), 0,
		      "Failed to unmount partition");
}

static void cleanup(struct fs_mount_t *mp)
{
	TC_PRINT("Clean %s\n", mp->mnt_point);

	zassert_equal(testfs_lfs_wipe_partition(mp), TC_PASS,
		      "Failed to clean partition");
}

ZTEST(littlefs, test_fs_open_flags_lfs)

{
	/* Using smallest partition for this tests as they do not write
	 * a lot of data, basically they just check flags.
	 */
	struct fs_mount_t *mp = &testfs_small_mnt;

	cleanup(mp);
	mp->flags = 0;
	mount(mp);

	test_fs_open_flags();

	unmount(mp);

}
```

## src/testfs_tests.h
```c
/*
 * Copyright (c) 2019 Peter Bigot Consulting, LLC
 *
 * SPDX-License-Identifier: Apache-2.0
 */

#ifndef _ZEPHYR_TESTS_SUBSYS_FS_LITTLEFS_TESTFS_TESTS_H_
#define  _ZEPHYR_TESTS_SUBSYS_FS_LITTLEFS_TESTFS_TESTS_H_

/* Tests in test_util */
void test_util_path_init_base(void);
void test_util_path_init_overrun(void);
void test_util_path_init_extended(void);
void test_util_path_extend(void);
void test_util_path_extend_up(void);
void test_util_path_extend_overrun(void);

/* Tests in test_lfs_basic */
void test_lfs_basic(void);

/* Tests in test_lfs_dirops */
void test_lfs_dirops(void);

/* Tests in test_lfs_perf */
void test_lfs_perf(void);

/* Test fs_open flags */
void test_fs_open_flags_lfs(void);

/* Test fs_mount flags */
void test_fs_mount_flags_lfs(void);

#endif /* _ZEPHYR_TESTS_SUBSYS_FS_LITTLEFS_TESTFS_TESTS_H_ */
```

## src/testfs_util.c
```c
/*
 * Copyright (c) 2019 Peter Bigot Consulting, LLC
 *
 * SPDX-License-Identifier: Apache-2.0
 */

#include <string.h>
#include <errno.h>
#include <zephyr/sys/__assert.h>
#include <zephyr/ztest.h>
#include "testfs_util.h"

static const char *path_vextend(struct testfs_path *pp,
				va_list ap)
{
	const char *ep = va_arg(ap, const char *);
	const char *endp = pp->path + sizeof(pp->path);

	while (ep) {
		size_t len = strlen(ep);
		char *eos = pp->eos;
		size_t rem = (endp - eos);

		if (strcmp(ep, "..") == 0) {
			char *sp = strrchr(pp->path, '/');

			if (sp == pp->path) {
				eos = sp + 1;
			} else {
				eos = sp;
			}
		} else if ((1 + len + 1) < rem) { /* /, ep, EOS */
			*eos = '/';
			++eos;
			memcpy(eos, ep, len);
			eos += len;
		} else {
			break;
		}
		*eos = 0;
		pp->eos = eos;

		ep = va_arg(ap, const char *);
	}
	return pp->path;
}

const char *testfs_path_init(struct testfs_path *pp,
			     const struct fs_mount_t *mp,
			     ...)
{
	va_list ap;

	if (mp == NULL) {
		pp->path[0] = '/';
		pp->eos = pp->path + 1;
	} else {
		size_t len = strlen(mp->mnt_point);

		__ASSERT('/' == mp->mnt_point[0], "relative mount point");
		if ((len + 1) >= sizeof(pp->path)) {
			len = sizeof(pp->path) - 1;
		}
		strncpy(pp->path, mp->mnt_point, len);
		pp->eos = pp->path + len;
	}
	*pp->eos = '\0';

	va_start(ap, mp);
	path_vextend(pp, ap);
	va_end(ap);
	return pp->path;
}

const char *testfs_path_extend(struct testfs_path *pp,
			       ...)
{
	va_list ap;

	va_start(ap, pp);
	path_vextend(pp, ap);
	va_end(ap);

	return pp->path;
}

int testfs_write_constant(struct fs_file_t *fp,
			  uint8_t value,
			  unsigned int len)
{
	uint8_t buffer[TESTFS_BUFFER_SIZE];
	unsigned int rem = len;

	memset(buffer, value, sizeof(buffer));

	while (rem > 0) {
		unsigned int count = sizeof(buffer);

		if (count > rem) {
			count = rem;
		}

		ssize_t rc = fs_write(fp, buffer, count);

		if (rc < 0) {
			return rc;
		}

		rem -= count;
	}

	return len;
}

int testfs_verify_constant(struct fs_file_t *fp,
			   uint8_t value,
			   unsigned int len)
{
	uint8_t buffer[TESTFS_BUFFER_SIZE];
	unsigned int match = 0;

	while (len > 0) {
		unsigned int count = sizeof(buffer);

		if (count > len) {
			count = len;
		}

		int rc = fs_read(fp, buffer, count);

		if (rc < 0) {
			return rc;
		}

		if (rc > count) {
			return -EIO;
		}

		for (unsigned int i = 0; i < rc; ++i) {
			if (value != buffer[i]) {
				break;
			}
			++match;
		}

		if (rc < count) {
			break;
		}

		len -= count;
	}
	return match;
}

int testfs_write_incrementing(struct fs_file_t *fp,
			      uint8_t value,
			      unsigned int len)
{
	uint8_t buffer[TESTFS_BUFFER_SIZE];
	unsigned int rem = len;

	while (rem > 0) {
		unsigned int count = sizeof(buffer);

		if (count > rem) {
			count = rem;
		}

		for (unsigned int i = 0; i < count; ++i) {
			buffer[i] = value++;
		}

		ssize_t rc = fs_write(fp, buffer, count);

		if (rc < 0) {
			return rc;
		}

		rem -= count;
	}

	return len;
}

int testfs_verify_incrementing(struct fs_file_t *fp,
			       uint8_t value,
			       unsigned int len)
{
	uint8_t buffer[TESTFS_BUFFER_SIZE];
	unsigned int match = 0;

	while (len > 0) {
		unsigned int count = sizeof(buffer);

		if (count > len) {
			count = len;
		}

		int rc = fs_read(fp, buffer, count);

		if (rc < 0) {
			return rc;
		}

		if (rc > count) {
			return -EIO;
		}

		for (unsigned int i = 0; i < rc; ++i) {
			if (value++ != buffer[i]) {
				break;
			}
			++match;
		}

		if (rc < count) {
			break;
		}

		len -= count;
	}
	return match;
}

int testfs_build(struct testfs_path *root,
		 const struct testfs_bcmd *cp)
{
	int rc;

	while (!TESTFS_BCMD_IS_END(cp)) {

		if (TESTFS_BCMD_IS_FILE(cp)) {
			struct fs_file_t file;

			fs_file_t_init(&file);
			rc = fs_open(&file,
				     testfs_path_extend(root,
							cp->name,
							TESTFS_PATH_END),
				     FS_O_CREATE | FS_O_RDWR);
			TC_PRINT("create at %s with %u from 0x%02x: %d\n",
				 root->path, cp->size, cp->value, rc);
			if (rc == 0) {
				rc = testfs_write_incrementing(&file, cp->value, cp->size);
				(void)fs_close(&file);
			}
			testfs_path_extend(root, "..", TESTFS_PATH_END);

			if (rc < 0) {
				TC_PRINT("FAILED create/write %s: %d\n",
					 root->path, rc);
				return rc;
			}

		} else if (TESTFS_BCMD_IS_ENTER_DIR(cp)) {
			testfs_path_extend(root,
					   cp->name,
					   TESTFS_PATH_END);
			rc = fs_mkdir(root->path);
			TC_PRINT("mkdir %s: %d\n", root->path, rc);
			if (rc < 0) {
				return rc;
			}
		} else if (TESTFS_BCMD_IS_EXIT_DIR(cp)) {
			TC_PRINT("exit directory %s\n", root->path);
			testfs_path_extend(root, "..", TESTFS_PATH_END);
		} else {
			TC_PRINT("ERROR: unexpected build command");
			return -EINVAL;
		}
		++cp;
	}
	return 0;
}

/* Check the found entry against a probably match.  Recurse into
 * matched directories.
 *
 * Sets the matched field of *cp if all tests pass.
 *
 * Return a negative error, or a nonnegative count of foreign
 * files.
 */
static int check_layout_entry(struct testfs_path *pp,
			      const struct fs_dirent *statp,
			      struct testfs_bcmd *cp,
			      struct testfs_bcmd *ecp)
{
	int rc = 0;
	unsigned int foreign = 0;

	/* Create the full path */
	testfs_path_extend(pp, statp->name,
			   TESTFS_PATH_END);

	/* Also check file content */
	if (statp->type == FS_DIR_ENTRY_FILE) {
		struct fs_file_t file;

		fs_file_t_init(&file);
		rc = fs_open(&file, pp->path, FS_O_CREATE | FS_O_RDWR);
		if (rc < 0) {
			TC_PRINT("%s: content check open failed: %d\n",
				 pp->path, rc);
			rc = -ENOENT;
			goto out;
		}
		rc = testfs_verify_incrementing(&file, cp->value, cp->size);
		if (rc != cp->size) {
			TC_PRINT("%s: content check failed: %d\n",
				 pp->path, rc);
			if (rc >= 0) {
				rc = -EIO;
			}
			goto out;
		}
		rc = fs_close(&file);
		if (rc != 0) {
			TC_PRINT("%s: content check close failed: %d\n",
				 pp->path, rc);
		}
	} else if (statp->type == FS_DIR_ENTRY_DIR) {
		rc = testfs_bcmd_verify_layout(pp,
					       cp + 1,
					       testfs_bcmd_exitdir(cp, ecp));
		if (rc >= 0) {
			foreign = rc;
		}
	}

out:
	testfs_path_extend(pp, "..",
			   TESTFS_PATH_END);

	if (rc >= 0) {
		cp->matched = true;
		rc = foreign;
	}

	return rc;
}

int testfs_bcmd_verify_layout(struct testfs_path *pp,
			      struct testfs_bcmd *scp,
			      struct testfs_bcmd *ecp)
{
	struct fs_dir_t dir;
	unsigned int count = 0;
	unsigned int foreign = 0;
	struct testfs_bcmd *cp = scp;

	while (cp < ecp) {
		cp->matched = false;
		++cp;
	}

	fs_dir_t_init(&dir);

	int rc = fs_opendir(&dir, pp->path);

	if (rc != 0) {
		TC_PRINT("%s: opendir failed: %d\n", pp->path, rc);
		if (rc > 0) {
			rc = -EIO;
		}
		return rc;
	}

	TC_PRINT("check %s for %zu entries\n", pp->path, ecp - scp);
	while (rc >= 0) {
		struct fs_dirent stat;

		rc = fs_readdir(&dir, &stat);
		if (rc != 0) {
			TC_PRINT("readdir failed: %d", rc);
			rc = -EIO;
			break;
		}

		if (stat.name[0] == '\0') {
			break;
		}

		++count;

		cp = testfs_bcmd_find(&stat, scp, ecp);

		bool dotdir = ((stat.type == FS_DIR_ENTRY_DIR)
			       && ((strcmp(stat.name, ".") == 0)
				   || (strcmp(stat.name, "..") == 0)));

		TC_PRINT("%s %s%s%s %zu\n", pp->path,
			 stat.name,
			 (stat.type == FS_DIR_ENTRY_FILE) ? "" : "/",
			 dotdir ? " SYNTHESIZED"
			 : (cp == NULL) ? " FOREIGN"
			 : "",
			 stat.size);

		if (dotdir) {
			zassert_true(false,
				     "special directories observed");
		} else if (cp != NULL) {
			rc = check_layout_entry(pp, &stat, cp, ecp);
			if (rc > 0) {
				foreign += rc;
			}
		} else {
			foreign += 1;
		}
	}
	TC_PRINT("%s found %u entries, %u foreign\n", pp->path, count, foreign);

	int rc2 = fs_closedir(&dir);

	if (rc2 != 0) {
		TC_PRINT("%s: closedir failed: %d\n",
			 pp->path, rc2);
		if (rc >= 0) {
			rc = (rc2 >= 0) ? -EIO : rc2;
		}
	}

	if (rc >= 0) {
		rc = foreign;
	}

	return rc;
}

struct testfs_bcmd *testfs_bcmd_exitdir(struct testfs_bcmd *cp,
					struct testfs_bcmd *ecp)
{
	unsigned int level = 1;

	/* Skip to the paired EXIT_DIR */
	while ((level > 0) && (++cp < ecp)) {
		if (TESTFS_BCMD_IS_ENTER_DIR(cp)) {
			++level;
		} else if (TESTFS_BCMD_IS_EXIT_DIR(cp)) {
			--level;
		}
	}
	return cp;
}

struct testfs_bcmd *testfs_bcmd_find(struct fs_dirent *statp,
				     struct testfs_bcmd *scp,
				     struct testfs_bcmd *ecp)
{
	struct testfs_bcmd *cp = scp;

	while (cp < ecp) {
		if ((cp->type == statp->type)
		    && (cp->name != NULL)
		    && (strcmp(cp->name, statp->name) == 0)
		    && (cp->size == statp->size)) {
			return cp;
		}

		if (TESTFS_BCMD_IS_ENTER_DIR(cp)) {
			cp = testfs_bcmd_exitdir(cp, ecp);
		}
		++cp;
	}

	return NULL;
}
```
